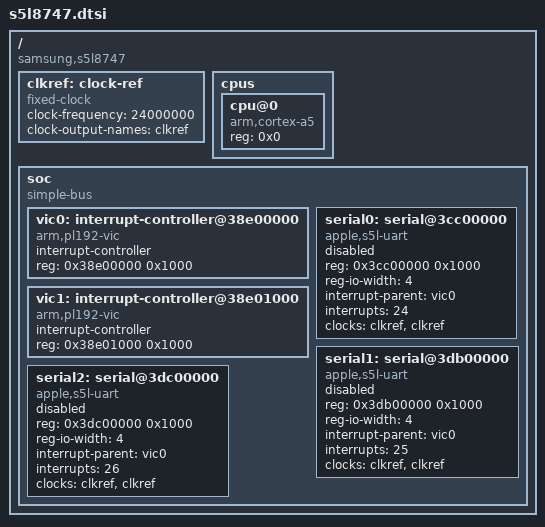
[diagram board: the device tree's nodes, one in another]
// SPDX-License-Identifier: GPL-2.0 OR MIT
/*
 * Samsung S578747 SoC device tree source
 *
 * Copyright (c) 2025 Nick Chan <towinchemi@gmail.com>
 */

/ {
	#address-cells = <1>;
	#size-cells = <1>;

	compatible = "samsung,s5l8747";

	clkref: clock-ref {
		compatible = "fixed-clock";
		#clock-cells = <0>;
		clock-frequency = <24000000>;
		clock-output-names = "clkref";
	};

	cpus {
		#address-cells = <1>;
		#size-cells = <0>;

		cpu@0 {
			compatible = "arm,cortex-a5";
			reg = <0x0>;
			device_type = "cpu";
		};
	};

	soc {
		compatible = "simple-bus";
		#address-cells = <1>;
		#size-cells = <1>;
		ranges;

		vic0: interrupt-controller@38e00000 {
			compatible = "arm,pl192-vic";
			interrupt-controller;
			reg = <0x38e00000 0x1000>;
			#interrupt-cells = <1>;
		};

		vic1: interrupt-controller@38e01000 {
			compatible = "arm,pl192-vic";
			interrupt-controller;
			reg = <0x38e01000 0x1000>;
			#interrupt-cells = <1>;
		};

		serial0: serial@3cc00000 {
			compatible = "apple,s5l-uart";
			reg = <0x3cc00000 0x1000>;
			reg-io-width = <4>;
			interrupt-parent = <&vic0>;
			interrupts = <24>;
			clocks = <&clkref>, <&clkref>;
			clock-names = "uart", "clk_uart_baud0";
			status = "disabled";
		};

		serial1: serial@3db00000 {
			compatible = "apple,s5l-uart";
			reg = <0x3db00000 0x1000>;
			reg-io-width = <4>;
			interrupt-parent = <&vic0>;
			interrupts = <25>;
			clocks = <&clkref>, <&clkref>;
			clock-names = "uart", "clk_uart_baud0";
			status = "disabled";
		};

		serial2: serial@3dc00000 {
			compatible = "apple,s5l-uart";
			reg = <0x3dc00000 0x1000>;
			reg-io-width = <4>;
			interrupt-parent = <&vic0>;
			interrupts = <26>;
			clocks = <&clkref>, <&clkref>;
			clock-names = "uart", "clk_uart_baud0";
			status = "disabled";
		};
	};
};

